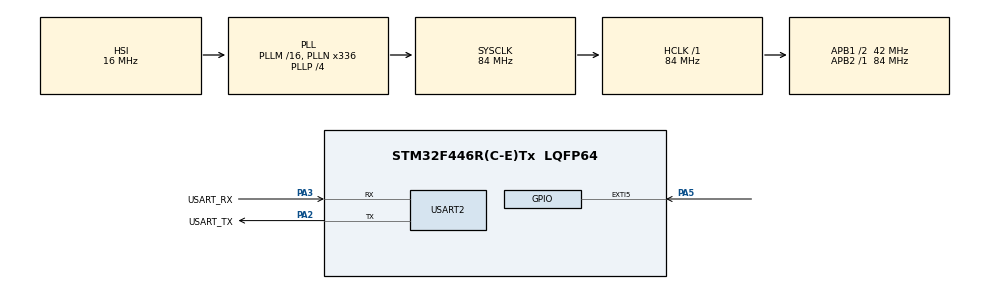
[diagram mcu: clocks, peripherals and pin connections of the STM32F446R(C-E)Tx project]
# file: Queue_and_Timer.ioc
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Mcu.Family=STM32F4
Mcu.Name=STM32F446R(C-E)Tx
Mcu.Package=LQFP64
NVIC.PriorityGroup=NVIC_PRIORITYGROUP_4
NVIC.TIM6_DAC_IRQn=true\:0\:0\:false\:false\:true\:false\:true\:true
NVIC.TimeBase=TIM6_DAC_IRQn
NVIC.TimeBaseIP=TIM6
NVIC.USART2_IRQn=true\:6\:0\:true\:false\:true\:true\:true\:true
PA13.GPIO_Label=TMS
PA13.Signal=SYS_JTMS-SWDIO
PA14.GPIO_Label=TCK
PA14.Signal=SYS_JTCK-SWCLK
PA2.GPIO_Label=USART_TX
PA2.Mode=Asynchronous
PA2.Signal=USART2_TX
PA3.GPIO_Label=USART_RX
PA3.Mode=Asynchronous
PA3.Signal=USART2_RX
PA5.Signal=GPXTI5
PB3.GPIO_Label=SWO
PB3.Signal=SYS_JTDO-SWO
PC14-OSC32_IN.Signal=RCC_OSC32_IN
PC15-OSC32_OUT.Signal=RCC_OSC32_OUT
PH0-OSC_IN.Signal=RCC_OSC_IN
PH1-OSC_OUT.Signal=RCC_OSC_OUT
ProjectManager.HeapSize=0x200
ProjectManager.StackSize=0x400
ProjectManager.TargetToolchain=STM32CubeIDE
RCC.AHBFreq_Value=84000000
RCC.APB1CLKDivider=RCC_HCLK_DIV2
RCC.APB1Freq_Value=42000000
RCC.APB1TimFreq_Value=84000000
RCC.APB2Freq_Value=84000000
RCC.APB2TimFreq_Value=84000000
RCC.CortexFreq_Value=84000000
RCC.FLatency-AdvancedSettings=FLASH_LATENCY_2
RCC.HCLKFreq_Value=84000000
RCC.HSE_VALUE=8000000
RCC.HSI_VALUE=16000000
RCC.LSE_VALUE=32768
RCC.PLLN=336
RCC.PLLP=RCC_PLLP_DIV4
RCC.SYSCLKFreq_VALUE=84000000
RCC.SYSCLKSource=RCC_SYSCLKSOURCE_PLLCLK
RCC.USBFreq_Value=168000000
RCC.VCOOutputFreq_Value=336000000
RTC.HourFormat=RTC_HOURFORMAT_12
USART2.VirtualMode=VM_ASYNC
VP_RTC_VS_RTC_Activate.Mode=RTC_Enabled
VP_SYS_VS_tim6.Mode=TIM6
board=NUCLEO-F446RE

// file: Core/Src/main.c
/* USER CODE BEGIN Header */
/**
  ******************************************************************************
  * @file           : main.c
  * @brief          : Main program body
  ******************************************************************************
  * @attention
  *
  * Copyright (c) 2025 STMicroelectronics.
  * All rights reserved.
  *
  * This software is licensed under terms that can be found in the LICENSE file
  * in the root directory of this software component.
  * If no LICENSE file comes with this software, it is provided AS-IS.
  *
  ******************************************************************************
  */
/* USER CODE END Header */
#include "main.h"

/* USER CODE BEGIN Includes */
#include <stdio.h>
/* USER CODE END Includes */

RTC_HandleTypeDef hrtc;

UART_HandleTypeDef huart2;

/* USER CODE BEGIN PV */
TaskHandle_t handle_menu_task;
  TaskHandle_t handle_cmd_task;
  TaskHandle_t handle_print_task;
  TaskHandle_t handle_led_task;
  TaskHandle_t handle_rtc_task;

  QueueHandle_t q_data;            // queue to get the data from the user
  QueueHandle_t q_print;           // queue to be used for the print

  BaseType_t status;
  volatile uint8_t user_data;
  state_t curr_state=sMainMenu;

  TimerHandle_t handle_led_timer[4];  // each element of the array will handle one timer object for one led effect
  TimerHandle_t rtc_timer;
/* USER CODE END PV */

void SystemClock_Config(void);
static void MX_GPIO_Init(void);
static void MX_RTC_Init(void);
static void MX_USART2_UART_Init(void);
/* USER CODE BEGIN PFP */
void led_effect_callback(TimerHandle_t xTimer);
/* USER CODE END PFP */

int main(void)
{

  /* MCU Configuration--------------------------------------------------------*/

  /* Reset of all peripherals, Initializes the Flash interface and the Systick. */
  HAL_Init();

  /* Configure the system clock */
  SystemClock_Config();

  /* Initialize all configured peripherals */
  MX_GPIO_Init();
  MX_RTC_Init();
  MX_USART2_UART_Init();
  /* USER CODE BEGIN 2 */
  status=xTaskCreate(menu_task,"Menu task",200,NULL,2,&handle_menu_task);
  configASSERT(status == pdPASS);

  status=xTaskCreate(cmd_task,"CMD task",200,NULL,2,&handle_cmd_task);
  configASSERT(status == pdPASS);

  status=xTaskCreate(print_task,"Print task",200,NULL,2,&handle_print_task);
  configASSERT(status == pdPASS);

  status=xTaskCreate(led_task,"LED task",200,NULL,2,&handle_led_task);
  configASSERT(status == pdPASS);

  status=xTaskCreate(rtc_task,"RTC task",200,NULL,2,&handle_rtc_task);
  configASSERT(status == pdPASS);

   // Queue creation
   q_data = xQueueCreate(10,sizeof(char)); // no of items is 10 and each item is of size char
   configASSERT(q_data != NULL); // xQueueCreate returns NULL id queue is not created

   q_print= xQueueCreate(10,sizeof(size_t)); //size of the pointer pointed to
   configASSERT(q_print != NULL);

   //Create software timer for the LED effects

   for(int i=0;i<4;i++)
   {
	   handle_led_timer[i]=xTimerCreate("Led_Timer",pdMS_TO_TICKS(500),pdTRUE,(void *)(i+1),led_effect_callback);
   }

   // Prepares the UART peripheral to receive data in interrupt mode
   HAL_UART_Receive_IT(&huart2, (uint8_t *)&user_data, 1);

   //Start task scheduler
   vTaskStartScheduler();

  /* USER CODE END 2 */

  /* Infinite loop */
  while (1)
  {

  }
}

void SystemClock_Config(void)
{
  RCC_OscInitTypeDef RCC_OscInitStruct = {0};
  RCC_ClkInitTypeDef RCC_ClkInitStruct = {0};

  /** Configure the main internal regulator output voltage
  */
  __HAL_RCC_PWR_CLK_ENABLE();
  __HAL_PWR_VOLTAGESCALING_CONFIG(PWR_REGULATOR_VOLTAGE_SCALE3);

  /** Initializes the RCC Oscillators according to the specified parameters
  * in the RCC_OscInitTypeDef structure.
  */
  RCC_OscInitStruct.OscillatorType = RCC_OSCILLATORTYPE_HSI|RCC_OSCILLATORTYPE_LSI;
  RCC_OscInitStruct.LSEState = RCC_LSE_OFF;
  RCC_OscInitStruct.HSIState = RCC_HSI_ON;
  RCC_OscInitStruct.HSICalibrationValue = RCC_HSICALIBRATION_DEFAULT;
  RCC_OscInitStruct.LSIState = RCC_LSI_ON;
  RCC_OscInitStruct.PLL.PLLState = RCC_PLL_ON;
  RCC_OscInitStruct.PLL.PLLSource = RCC_PLLSOURCE_HSI;
  RCC_OscInitStruct.PLL.PLLM = 16;
  RCC_OscInitStruct.PLL.PLLN = 336;
  RCC_OscInitStruct.PLL.PLLP = RCC_PLLP_DIV4;
  RCC_OscInitStruct.PLL.PLLQ = 2;
  RCC_OscInitStruct.PLL.PLLR = 2;
  if (HAL_RCC_OscConfig(&RCC_OscInitStruct) != HAL_OK)
  {
    Error_Handler();
  }

  /** Initializes the CPU, AHB and APB buses clocks
  */
  RCC_ClkInitStruct.ClockType = RCC_CLOCKTYPE_HCLK|RCC_CLOCKTYPE_SYSCLK
                              |RCC_CLOCKTYPE_PCLK1|RCC_CLOCKTYPE_PCLK2;
  RCC_ClkInitStruct.SYSCLKSource = RCC_SYSCLKSOURCE_PLLCLK;
  RCC_ClkInitStruct.AHBCLKDivider = RCC_SYSCLK_DIV1;
  RCC_ClkInitStruct.APB1CLKDivider = RCC_HCLK_DIV2;
  RCC_ClkInitStruct.APB2CLKDivider = RCC_HCLK_DIV1;

  if (HAL_RCC_ClockConfig(&RCC_ClkInitStruct, FLASH_LATENCY_2) != HAL_OK)
  {
    Error_Handler();
  }
}

static void MX_RTC_Init(void)
{

  /** Initialize RTC Only
  */
  hrtc.Instance = RTC;
  hrtc.Init.HourFormat = RTC_HOURFORMAT_12;
  hrtc.Init.AsynchPrediv = 127;
  hrtc.Init.SynchPrediv = 255;
  hrtc.Init.OutPut = RTC_OUTPUT_DISABLE;
  hrtc.Init.OutPutPolarity = RTC_OUTPUT_POLARITY_HIGH;
  hrtc.Init.OutPutType = RTC_OUTPUT_TYPE_OPENDRAIN;
  if (HAL_RTC_Init(&hrtc) != HAL_OK)
  {
    Error_Handler();
  }

}

static void MX_USART2_UART_Init(void)
{

  huart2.Instance = USART2;
  huart2.Init.BaudRate = 115200;
  huart2.Init.WordLength = UART_WORDLENGTH_8B;
  huart2.Init.StopBits = UART_STOPBITS_1;
  huart2.Init.Parity = UART_PARITY_NONE;
  huart2.Init.Mode = UART_MODE_TX_RX;
  huart2.Init.HwFlowCtl = UART_HWCONTROL_NONE;
  huart2.Init.OverSampling = UART_OVERSAMPLING_16;
  if (HAL_UART_Init(&huart2) != HAL_OK)
  {
    Error_Handler();
  }

}

static void MX_GPIO_Init(void)
{
  GPIO_InitTypeDef GPIO_InitStruct = {0};

  /* GPIO Ports Clock Enable */
  __HAL_RCC_GPIOC_CLK_ENABLE();
  __HAL_RCC_GPIOH_CLK_ENABLE();
  __HAL_RCC_GPIOA_CLK_ENABLE();
  __HAL_RCC_GPIOB_CLK_ENABLE();

  /*Configure GPIO pin : PA5 */
  GPIO_InitStruct.Pin = GPIO_PIN_5;
  GPIO_InitStruct.Mode = GPIO_MODE_IT_RISING;
  GPIO_InitStruct.Pull = GPIO_NOPULL;
  HAL_GPIO_Init(GPIOA, &GPIO_InitStruct);

}

/* USER CODE BEGIN 4 */

void led_effect_callback(TimerHandle_t xTimer)
{
	int id;
	id=(uint32_t)pvTimerGetTimerID(xTimer);
	switch(id)
	{
	case 1:
		led_effect1();
		break;
	case 2:
		led_effect2();
		break;
	case 3:
		led_effect3();
		break;
	case 4:
		led_effect4();
		break;
	}
}
// This function is called once the data from the user is received by the UART peripheral
void HAL_UART_RxCpltCallback(UART_HandleTypeDef *huart)
{

	uint8_t dummy;
	/*TODO: check : is queue full ? */
	if(xQueueIsQueueFullFromISR(q_data)==pdFALSE)
		{
			/*Queue is not full if the body of the if condition is entered */

			/* Enqueue data byte - add data item to the end of queue*/
		xQueueSendFromISR(q_data, (void *)&user_data, NULL);

		}
	else
	{
			/*Queue is full */

			if(user_data == '\n')
			{
				/*user_data = '\n' */

				/*TODO: make sure that last data byte of the queue is '\n' */
				xQueueReceiveFromISR(q_data, (void *)&dummy, NULL);
				xQueueSendFromISR(q_data, (void *)&user_data, NULL);
		     }

	}
		/*TODO: send notification to command handling task if user_data = '\n' */
        if(user_data == '\n')
        	xTaskNotifyFromISR(handle_cmd_task,0,eNoAction,NULL);

		/* TODO: Enable UART data byte reception again in IT mode */
        HAL_UART_Receive_IT(&huart2,(uint8_t *) &user_data, 1);
}
/* USER CODE END 4 */

void HAL_TIM_PeriodElapsedCallback(TIM_HandleTypeDef *htim)
{
  if (htim->Instance == TIM6)
  {
    HAL_IncTick();
  }
}

void Error_Handler(void)
{
  /* USER CODE BEGIN Error_Handler_Debug */
  /* User can add his own implementation to report the HAL error return state */
  __disable_irq();
  while (1)
  {
  };
  /* USER CODE END Error_Handler_Debug */
}
